# ATtiny11 register map
Vendor: Atmel; File version: 1.0
CPU: other r0p0, little endian, no MPU, no FPU, 4 interrupt priority bits
Registers are 8-bit, read-write, reset 0x0 unless marked. A register's access mark holds for its fields unless they carry their own. Offsets are from the block's base; lines under a group give offsets from that group; [hi:lo] are bit positions; {n}, {i} and the like mark numbered series; 'fields as' and 'values as' point back to an identical list; <NAME> marks a mode.

## Memory map
0x00800000 FUSE size 0x1 — Fuses
0x00800000 LOCKBIT size 0x1 — Lockbits
0x00800008 AC size 0x1 — Analog Comparator
0x00800016 PORTB size 0x3 — I/O Port
0x00800021 WDT size 0x1 — Watchdog Timer
0x00800032 TC0 blocks up to offset 0x8 — Timer/Counter, 8-bit
0x00800034 CPU size 0x2 — CPU Registers
0x0080003A EXINT size 0x2 — External Interrupts

## Interrupts
0 RESET (CPU) — External Reset, Power-on Reset and Watchdog Reset
1 INT0 (CPU) — External Interrupt 0
2 IO_PINS (CPU) — External Interrupt Request 0
3 TIMER0_OVF (CPU) — Timer/Counter0 Overflow
4 ANA_COMP (CPU) — Analog Comparator

## AC — Analog Comparator
Base 0x00800008
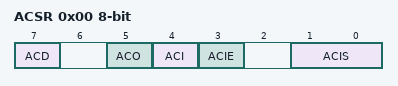
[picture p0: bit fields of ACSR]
0x00 ACSR — Analog Comparator Control And Status Register
  [7] ACD — Analog Comparator Disable
  [5] ACO — Analog Comparator Output
  [4] ACI — Analog Comparator Interrupt Flag
  [3] ACIE — Analog Comparator Interrupt Enable
  [1:0] ACIS — Analog Comparator Interrupt Mode Select bits
    0=INTERRUPT_ON_TOGGLE; 2=INTERRUPT_ON_FALLING_EDGE; 3=INTERRUPT_ON_RISING_EDGE

## CPU — CPU Registers
Base 0x00800034
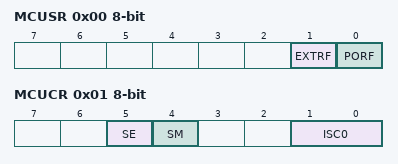
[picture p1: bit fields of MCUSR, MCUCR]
0x00 MCUSR — MCU Status register
  [1] EXTRF — External Reset Flag
  [0] PORF — Power-On Reset Flag
0x01 MCUCR — MCU Control Register
  [5] SE — Sleep Enable
  [4] SM — Sleep Mode
    0=IDLE; 1=PDOWN (Power Down)
  [1:0] ISC0 — Interrupt Sense Control 0 bits
    0=LOW_LEVEL_OF_INTX; 1=ANY_LOGICAL_CHANGE_IN_INTX; 2=FALLING_EDGE_OF_INTX; 3=RISING_EDGE_OF_INTX

## EXINT — External Interrupts
Base 0x0080003A
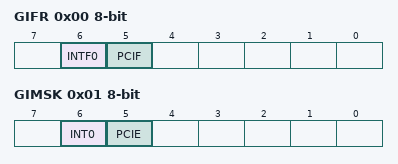
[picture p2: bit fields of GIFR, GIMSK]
0x00 GIFR — General Interrupt Flag register
  [6] INTF0 — External Interrupt Flag 0
  [5] PCIF — Pin Change Interrupt Flag
0x01 GIMSK — General Interrupt Mask Register
  [6] INT0 — External Interrupt Request 0 Enable
  [5] PCIE — Pin Change Interrupt Enable

## FUSE — Fuses
Base 0x00800000
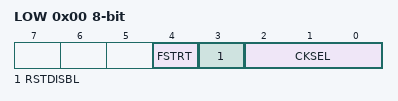
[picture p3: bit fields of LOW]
0x00 LOW
  [4] FSTRT — Short start-up time selected
  [3] RSTDISBL — External reset function of PB5 disabled
  [2:0] CKSEL — Clock Select
    0=EXTCLK (External Clock); 4=INTRCOSC (Internal RC Oscillator); 5=EXTRCOSC (External RC Oscillator); 6=EXTLOFXTAL (External Low-frequency Crystal); 7=EXTXTALCRES (External Crystal / Ceramic Resonator)

## LOCKBIT — Lockbits
Base 0x00800000
0x00 LOCKBIT
  [2:1] LB — Memory Lock
    0=PROG_VER_DISABLED (Further programming and verification disabled); 1=PROG_DISABLED (Further programming disabled); 3=NO_LOCK (No memory lock features enabled)

## PORTB — I/O Port
Base 0x00800016
0x00 PINB — Input Pins, Port B
0x01 DDRB — Data Direction Register, Port B
0x02 PORTB — Data Register, Port B

## TC0 — Timer/Counter, 8-bit
Base 0x00800032
0x00 TCNT0 — Timer Counter 0
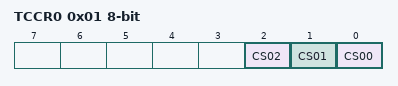
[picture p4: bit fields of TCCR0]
0x01 TCCR0 — Timer/Counter0 Control Register
  [2] CS02 — Clock Select0 bit 2
    0=NO_CLOCK_SOURCE_STOPPED; 1=RUNNING_NO_PRESCALING
  [1] CS01 — Clock Select0 bit 1
  [0] CS00 — Clock Select0 bit 0
0x06 TIFR — Timer/Counter Interrupt Flag register
  [1] TOV0 — Timer/Counter0 Overflow Flag
0x07 TIMSK — Timer/Counter Interrupt Mask Register
  [1] TOIE0 — Timer/Counter0 Overflow Interrupt Enable

## WDT — Watchdog Timer
Base 0x00800021
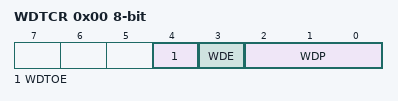
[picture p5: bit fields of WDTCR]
0x00 WDTCR — Watchdog Timer Control Register
  [4] WDTOE — RW
  [3] WDE — Watch Dog Enable
  [2:0] WDP — Watch Dog Timer Prescaler bits
    0=OSCILLATOR_CYCLES_16K; 1=OSCILLATOR_CYCLES_32K; 2=OSCILLATOR_CYCLES_64K; 3=OSCILLATOR_CYCLES_128K; 4=OSCILLATOR_CYCLES_256K; 5=OSCILLATOR_CYCLES_512K; 6=OSCILLATOR_CYCLES_1024K; 7=OSCILLATOR_CYCLES_2048K
